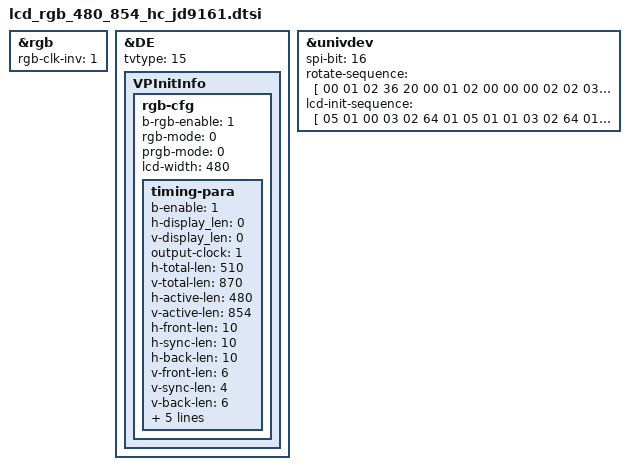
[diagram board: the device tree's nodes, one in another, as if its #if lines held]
&rgb {
	rgb-clk-inv = <1>;
};

&DE {
	tvtype = <15>;
	VPInitInfo {
		rgb-cfg{
			b-rgb-enable = <1>;
			/*
			 * 0: MODE_PRGB
			 * 1: MODE_SRGB
			 */
			rgb-mode = <0>;
			/*
			 * 0: MODE_PRGB_888_10bit
			 * 1: MODE_PRGB_666
			 */
			prgb-mode = <0>;
			lcd-width = <480>;
			timing-para {
				/* bool type, 0 or 1*/
				b-enable = <1>;

				h-display_len = <0>;
				v-display_len = <0>;

				/*
				 * VPO_RGB_CLOCK_27M = 1,
				 * VPO_RGB_CLOCK_33M = 2,
				 * VPO_RGB_CLOCK_49M = 3,
				 * VPO_RGB_CLOCK_66M = 4,
				 * VPO_RGB_CLOCK_74M = 5,
				 * VPO_RGB_CLOCK_85M = 6,
				 * VPO_RGB_CLOCK_108M = 7,
				 * VPO_RGB_CLOCK_6_6M = 8,
				 * VPO_RGB_CLOCK_9M = 9,
				 * VPO_RGB_CLOCK_39_6M = 10,
				 * VPO_RGB_CLOCK_74_25M = 11,
				 * VPO_RGB_CLOCK_148_5M = 12,
				 * VPO_RGB_CLOCK_54M = 13,
				 * VPO_RGB_CLOCK_132M = 14,//H1600
				 * VPO_RGB_CLOCK_297M = 15,//H1600 only De4k
				 * VPO_RGB_CLOCK_DPLL = 0xFF,//H1600
				*/
				output-clock = <1>;

				h-total-len = <510>;
				v-total-len = <870>;

				h-active-len = <480>;
				v-active-len = <854>;

				h-front-len = <10>;
				h-sync-len = <10>;
				h-back-len = <10>;

				v-front-len = <6>;
				v-sync-len = <4>;
				v-back-len = <6>;

				/* bool type, 0 or 1*/
				h-sync-level = <0>;
				/* bool type, 0 or 1*/
				v-sync-level = <0>;

				/* bool type, 0 or 1*/
				active-polarity = <1>;
				frame-rate = <60000>;

				/*
				31	De_dig_pll_en
				25:16	DE_DIG_PLL_M_ctrl
				13:8	DE_DIG_PLL_N_ctrl
				5:0	DE_DIG_PLL_L_ctrl
				de_digpll_clock = 24 *(M+1)/((N+1)*(L+1))
				*/
				dpll-clock-reg-value = <0x0>;
			};
		};
	};
};

#ifdef LCD_UNIVDEV_ENABLED
&univdev{
	spi-bit = <16>;
	rotate-sequence = [	//direction cmds length data
		00 01 02 36 20
		00 01 02 00 00
		00 02 02 03 40
		01 01 02 36 20
		01 01 02 00 00
		01 02 02 02 40
	];
	lcd-init-sequence = [
	05 01 00
	03 02 64 01
	05 01 01
	03 02 64 01
	01 02 ff 20
	01 02 00 00
	02 02 80 40
	01 02 ff 20
	01 02 01 00
	02 02 09 40
	01 02 ff 20
	01 02 02 00
	02 02 01 40
	01 02 ff 20
	01 02 80 00
	02 02 80 40
	01 02 ff 20
	01 02 81 00
	02 02 09 40
	01 02 c4 20
	01 02 80 00
	02 02 30 40
	01 02 c4 20
	01 02 8a 00
	02 02 40 40
	01 02 f5 20
	01 02 b2 00
	02 02 15 40
	01 02 f5 20
	01 02 b3 00
	02 02 00 40
	01 02 f5 20
	01 02 b4 00
	02 02 15 40
	01 02 f5 20
	01 02 b5 00
	02 02 00 40
	01 02 b0 20
	01 02 8b 00
	02 02 40 40
	01 02 b0 20
	01 02 c6 00
	02 02 03 40
	01 02 b3 20
	01 02 90 00
	02 02 02 40
	01 02 b3 20
	01 02 92 00
	02 02 40 40
	01 02 b3 20
	01 02 a6 00
	02 02 20 40
	01 02 b3 20
	01 02 a7 00
	02 02 01 40
	01 02 c0 20
	01 02 90 00
	02 02 00 40
	01 02 c0 20
	01 02 91 00
	02 02 44 40
	01 02 c0 20
	01 02 92 00
	02 02 00 40
	01 02 c0 20
	01 02 93 00
	02 02 00 40
	01 02 c0 20
	01 02 94 00
	02 02 00 40
	01 02 c0 20
	01 02 95 00
	02 02 03 40
	01 02 c0 20
	01 02 b4 00
	02 02 10 40
	01 02 c0 20
	01 02 b5 00
	02 02 10 40
	01 02 c1 20
	01 02 81 00
	02 02 66 40
	01 02 c1 20
	01 02 a0 00
	02 02 ea 40
	01 02 c1 20
	01 02 a6 00
	02 02 01 40
	01 02 c1 20
	01 02 a7 00
	02 02 00 40
	01 02 c1 20
	01 02 a8 00
	02 02 00 40
	01 02 c4 20
	01 02 81 00
	02 02 81 40
	01 02 c5 20
	01 02 82 00
	02 02 83 40
	01 02 c5 20
	01 02 90 00
	02 02 96 40
	01 02 c5 20
	01 02 91 00
	02 02 34 40
	01 02 c5 20
	01 02 92 00
	02 02 06 40
	01 02 c5 20
	01 02 93 00
	02 02 91 40
	01 02 c5 20
	01 02 94 00
	02 02 33 40
	01 02 c5 20
	01 02 95 00
	02 02 34 40
	01 02 c5 20
	01 02 96 00
	02 02 23 40
	01 02 c5 20
	01 02 b1 00
	02 02 a9 40
	01 02 c5 20
	01 02 c0 00
	02 02 00 40
	01 02 ce 20
	01 02 80 00
	02 02 86 40
	01 02 ce 20
	01 02 81 00
	02 02 01 40
	01 02 ce 20
	01 02 82 00
	02 02 00 40
	01 02 ce 20
	01 02 83 00
	02 02 85 40
	01 02 ce 20
	01 02 84 00
	02 02 01 40
	01 02 ce 20
	01 02 85 00
	02 02 00 40
	01 02 ce 20
	01 02 a0 00
	02 02 18 40
	01 02 ce 20
	01 02 a1 00
	02 02 05 40
	01 02 ce 20
	01 02 a2 00
	02 02 03 40
	01 02 ce 20
	01 02 a3 00
	02 02 5b 40
	01 02 ce 20
	01 02 a4 00
	02 02 00 40
	01 02 ce 20
	01 02 a5 00
	02 02 00 40
	01 02 ce 20
	01 02 a6 00
	02 02 00 40
	01 02 ce 20
	01 02 a7 00
	02 02 18 40
	01 02 ce 20
	01 02 a8 00
	02 02 04 40
	01 02 ce 20
	01 02 a9 00
	02 02 03 40
	01 02 ce 20
	01 02 aa 00
	02 02 5c 40
	01 02 ce 20
	01 02 ab 00
	02 02 00 40
	01 02 ce 20
	01 02 ac 00
	02 02 00 40
	01 02 ce 20
	01 02 ad 00
	02 02 00 40
	01 02 ce 20
	01 02 b0 00
	02 02 18 40
	01 02 ce 20
	01 02 b1 00
	02 02 03 40
	01 02 ce 20
	01 02 b2 00
	02 02 03 40
	01 02 ce 20
	01 02 b3 00
	02 02 5d 40
	01 02 ce 20
	01 02 b4 00
	02 02 00 40
	01 02 ce 20
	01 02 b5 00
	02 02 00 40
	01 02 ce 20
	01 02 b6 00
	02 02 00 40
	01 02 ce 20
	01 02 b7 00
	02 02 18 40
	01 02 ce 20
	01 02 b8 00
	02 02 02 40
	01 02 ce 20
	01 02 b9 00
	02 02 03 40
	01 02 ce 20
	01 02 ba 00
	02 02 5e 40
	01 02 ce 20
	01 02 bb 00
	02 02 00 40
	01 02 ce 20
	01 02 bc 00
	02 02 00 40
	01 02 ce 20
	01 02 bd 00
	02 02 00 40
	01 02 cf 20
	01 02 c0 00
	02 02 01 40
	01 02 cf 20
	01 02 c1 00
	02 02 01 40
	01 02 cf 20
	01 02 c2 00
	02 02 20 40
	01 02 cf 20
	01 02 c3 00
	02 02 20 40
	01 02 cf 20
	01 02 c4 00
	02 02 00 40
	01 02 cf 20
	01 02 c5 00
	02 02 00 40
	01 02 cf 20
	01 02 c6 00
	02 02 01 40
	01 02 cf 20
	01 02 c7 00
	02 02 00 40
	01 02 cf 20
	01 02 c8 00
	02 02 00 40
	01 02 cf 20
	01 02 c9 00
	02 02 00 40
	01 02 cb 20
	01 02 c0 00
	02 02 00 40
	01 02 cb 20
	01 02 c1 00
	02 02 04 40
	01 02 cb 20
	01 02 c2 00
	02 02 04 40
	01 02 cb 20
	01 02 c3 00
	02 02 04 40
	01 02 cb 20
	01 02 c4 00
	02 02 04 40
	01 02 cb 20
	01 02 c5 00
	02 02 04 40
	01 02 cb 20
	01 02 c6 00
	02 02 00 40
	01 02 cb 20
	01 02 c7 00
	02 02 00 40
	01 02 cb 20
	01 02 c8 00
	02 02 00 40
	01 02 cb 20
	01 02 c9 00
	02 02 00 40
	01 02 cb 20
	01 02 ca 00
	02 02 00 40
	01 02 cb 20
	01 02 cb 00
	02 02 00 40
	01 02 cb 20
	01 02 cc 00
	02 02 00 40
	01 02 cb 20
	01 02 cd 00
	02 02 00 40
	01 02 cb 20
	01 02 ce 00
	02 02 00 40
	01 02 cb 20
	01 02 d0 00
	02 02 00 40
	01 02 cb 20
	01 02 d1 00
	02 02 00 40
	01 02 cb 20
	01 02 d2 00
	02 02 00 40
	01 02 cb 20
	01 02 d3 00
	02 02 00 40
	01 02 cb 20
	01 02 d4 00
	02 02 00 40
	01 02 cb 20
	01 02 d5 00
	02 02 00 40
	01 02 cb 20
	01 02 d6 00
	02 02 04 40
	01 02 cb 20
	01 02 d7 00
	02 02 04 40
	01 02 cb 20
	01 02 d8 00
	02 02 04 40
	01 02 cb 20
	01 02 d9 00
	02 02 04 40
	01 02 cb 20
	01 02 da 00
	02 02 04 40
	01 02 cb 20
	01 02 db 00
	02 02 00 40
	01 02 cb 20
	01 02 dc 00
	02 02 00 40
	01 02 cb 20
	01 02 dd 00
	02 02 00 40
	01 02 cb 20
	01 02 de 00
	02 02 00 40
	01 02 cb 20
	01 02 e0 00
	02 02 00 40
	01 02 cb 20
	01 02 e1 00
	02 02 00 40
	01 02 cb 20
	01 02 e2 00
	02 02 00 40
	01 02 cb 20
	01 02 e3 00
	02 02 00 40
	01 02 cb 20
	01 02 e4 00
	02 02 00 40
	01 02 cb 20
	01 02 e5 00
	02 02 00 40
	01 02 cb 20
	01 02 e6 00
	02 02 00 40
	01 02 cb 20
	01 02 e7 00
	02 02 00 40
	01 02 cb 20
	01 02 e8 00
	02 02 00 40
	01 02 cb 20
	01 02 e9 00
	02 02 00 40
	01 02 cb 20
	01 02 f0 00
	02 02 ff 40
	01 02 cb 20
	01 02 f1 00
	02 02 ff 40
	01 02 cb 20
	01 02 f2 00
	02 02 ff 40
	01 02 cb 20
	01 02 f3 00
	02 02 ff 40
	01 02 cb 20
	01 02 f4 00
	02 02 ff 40
	01 02 cb 20
	01 02 f5 00
	02 02 ff 40
	01 02 cb 20
	01 02 f6 00
	02 02 ff 40
	01 02 cb 20
	01 02 f7 00
	02 02 ff 40
	01 02 cb 20
	01 02 f8 00
	02 02 ff 40
	01 02 cb 20
	01 02 f9 00
	02 02 ff 40
	01 02 cc 20
	01 02 80 00
	02 02 00 40
	01 02 cc 20
	01 02 81 00
	02 02 26 40
	01 02 cc 20
	01 02 82 00
	02 02 09 40
	01 02 cc 20
	01 02 83 00
	02 02 0b 40
	01 02 cc 20
	01 02 84 00
	02 02 01 40
	01 02 cc 20
	01 02 85 00
	02 02 25 40
	01 02 cc 20
	01 02 86 00
	02 02 00 40
	01 02 cc 20
	01 02 87 00
	02 02 00 40
	01 02 cc 20
	01 02 88 00
	02 02 00 40
	01 02 cc 20
	01 02 89 00
	02 02 00 40
	01 02 cc 20
	01 02 90 00
	02 02 00 40
	01 02 cc 20
	01 02 91 00
	02 02 00 40
	01 02 cc 20
	01 02 92 00
	02 02 00 40
	01 02 cc 20
	01 02 93 00
	02 02 00 40
	01 02 cc 20
	01 02 94 00
	02 02 00 40
	01 02 cc 20
	01 02 95 00
	02 02 00 40
	01 02 cc 20
	01 02 96 00
	02 02 00 40
	01 02 cc 20
	01 02 97 00
	02 02 00 40
	01 02 cc 20
	01 02 98 00
	02 02 00 40
	01 02 cc 20
	01 02 99 00
	02 02 00 40
	01 02 cc 20
	01 02 9a 00
	02 02 00 40
	01 02 cc 20
	01 02 9b 00
	02 02 26 40
	01 02 cc 20
	01 02 9c 00
	02 02 0a 40
	01 02 cc 20
	01 02 9d 00
	02 02 0c 40
	01 02 cc 20
	01 02 9e 00
	02 02 02 40
	01 02 cc 20
	01 02 a0 00
	02 02 25 40
	01 02 cc 20
	01 02 a1 00
	02 02 00 40
	01 02 cc 20
	01 02 a2 00
	02 02 00 40
	01 02 cc 20
	01 02 a3 00
	02 02 00 40
	01 02 cc 20
	01 02 a4 00
	02 02 00 40
	01 02 cc 20
	01 02 a5 00
	02 02 00 40
	01 02 cc 20
	01 02 a6 00
	02 02 00 40
	01 02 cc 20
	01 02 a7 00
	02 02 00 40
	01 02 cc 20
	01 02 a8 00
	02 02 00 40
	01 02 cc 20
	01 02 a9 00
	02 02 00 40
	01 02 cc 20
	01 02 aa 00
	02 02 00 40
	01 02 cc 20
	01 02 ab 00
	02 02 00 40
	01 02 cc 20
	01 02 ac 00
	02 02 00 40
	01 02 cc 20
	01 02 ad 00
	02 02 00 40
	01 02 cc 20
	01 02 ae 00
	02 02 00 40
	01 02 cc 20
	01 02 b0 00
	02 02 00 40
	01 02 cc 20
	01 02 b1 00
	02 02 25 40
	01 02 cc 20
	01 02 b2 00
	02 02 0c 40
	01 02 cc 20
	01 02 b3 00
	02 02 0a 40
	01 02 cc 20
	01 02 b4 00
	02 02 02 40
	01 02 cc 20
	01 02 b5 00
	02 02 26 40
	01 02 cc 20
	01 02 b6 00
	02 02 00 40
	01 02 cc 20
	01 02 b7 00
	02 02 00 40
	01 02 cc 20
	01 02 b8 00
	02 02 00 40
	01 02 cc 20
	01 02 b9 00
	02 02 00 40
	01 02 cc 20
	01 02 c0 00
	02 02 00 40
	01 02 cc 20
	01 02 c1 00
	02 02 00 40
	01 02 cc 20
	01 02 c2 00
	02 02 00 40
	01 02 cc 20
	01 02 c3 00
	02 02 00 40
	01 02 cc 20
	01 02 c4 00
	02 02 00 40
	01 02 cc 20
	01 02 c5 00
	02 02 00 40
	01 02 cc 20
	01 02 c6 00
	02 02 00 40
	01 02 cc 20
	01 02 c7 00
	02 02 00 40
	01 02 cc 20
	01 02 c8 00
	02 02 00 40
	01 02 cc 20
	01 02 c9 00
	02 02 00 40
	01 02 cc 20
	01 02 ca 00
	02 02 00 40
	01 02 cc 20
	01 02 cb 00
	02 02 25 40
	01 02 cc 20
	01 02 cc 00
	02 02 0b 40
	01 02 cc 20
	01 02 cd 00
	02 02 09 40
	01 02 cc 20
	01 02 ce 00
	02 02 01 40
	01 02 cc 20
	01 02 d0 00
	02 02 26 40
	01 02 cc 20
	01 02 d1 00
	02 02 00 40
	01 02 cc 20
	01 02 d2 00
	02 02 00 40
	01 02 cc 20
	01 02 d3 00
	02 02 00 40
	01 02 cc 20
	01 02 d4 00
	02 02 00 40
	01 02 cc 20
	01 02 d5 00
	02 02 00 40
	01 02 cc 20
	01 02 d6 00
	02 02 00 40
	01 02 cc 20
	01 02 d7 00
	02 02 00 40
	01 02 cc 20
	01 02 d8 00
	02 02 00 40
	01 02 cc 20
	01 02 d9 00
	02 02 00 40
	01 02 cc 20
	01 02 da 00
	02 02 00 40
	01 02 cc 20
	01 02 db 00
	02 02 00 40
	01 02 cc 20
	01 02 dc 00
	02 02 00 40
	01 02 cc 20
	01 02 dd 00
	02 02 00 40
	01 02 cc 20
	01 02 de 00
	02 02 00 40
	01 02 d8 20
	01 02 00 00
	02 02 77 40
	01 02 d8 20
	01 02 01 00
	02 02 77 40
	01 02 d9 20
	01 02 00 00
	02 02 48 40
	01 02 e1 20
	01 02 00 00
	02 02 01 40
	01 02 e1 20
	01 02 01 00
	02 02 08 40
	01 02 e1 20
	01 02 02 00
	02 02 0d 40
	01 02 e1 20
	01 02 03 00
	02 02 0d 40
	01 02 e1 20
	01 02 04 00
	02 02 05 40
	01 02 e1 20
	01 02 05 00
	02 02 0f 40
	01 02 e1 20
	01 02 06 00
	02 02 0c 40
	01 02 e1 20
	01 02 07 00
	02 02 0b 40
	01 02 e1 20
	01 02 08 00
	02 02 02 40
	01 02 e1 20
	01 02 09 00
	02 02 06 40
	01 02 e1 20
	01 02 0a 00
	02 02 0b 40
	01 02 e1 20
	01 02 0b 00
	02 02 08 40
	01 02 e1 20
	01 02 0c 00
	02 02 0f 40
	01 02 e1 20
	01 02 0d 00
	02 02 12 40
	01 02 e1 20
	01 02 0e 00
	02 02 0d 40
	01 02 e1 20
	01 02 0f 00
	02 02 03 40
	01 02 e2 20
	01 02 00 00
	02 02 01 40
	01 02 e2 20
	01 02 01 00
	02 02 08 40
	01 02 e2 20
	01 02 02 00
	02 02 0d 40
	01 02 e2 20
	01 02 03 00
	02 02 0d 40
	01 02 e2 20
	01 02 04 00
	02 02 05 40
	01 02 e2 20
	01 02 05 00
	02 02 0f 40
	01 02 e2 20
	01 02 06 00
	02 02 0c 40
	01 02 e2 20
	01 02 07 00
	02 02 0b 40
	01 02 e2 20
	01 02 08 00
	02 02 02 40
	01 02 e2 20
	01 02 09 00
	02 02 06 40
	01 02 e2 20
	01 02 0a 00
	02 02 0b 40
	01 02 e2 20
	01 02 0b 00
	02 02 08 40
	01 02 e2 20
	01 02 0c 00
	02 02 0f 40
	01 02 e2 20
	01 02 0d 00
	02 02 12 40
	01 02 e2 20
	01 02 0e 00
	02 02 0d 40
	01 02 e2 20
	01 02 0f 00
	02 02 03 40
	01 02 c1 20
	01 02 a0 00
	02 02 ea 40
	01 02 c1 20
	01 02 a6 00
	02 02 01 40
	01 02 c1 20
	01 02 a7 00
	02 02 00 40
	01 02 c1 20
	01 02 a8 00
	02 02 00 40
	01 02 b0 20
	01 02 c6 00
	02 02 03 40
	01 02 c5 20
	01 02 81 00
	02 02 66 40
	01 02 f5 20
	01 02 b6 00
	02 02 06 40
	01 02 b0 20
	01 02 8b 00
	02 02 40 40
	01 02 ff 20
	01 02 00 00
	02 02 ff 40
	01 02 ff 20
	01 02 01 00
	02 02 ff 40
	01 02 ff 20
	01 02 02 00
	02 02 ff 40
	01 02 11 20
	01 02 00 00
	02 02 00 40
	03 01 78
	01 02 29 20
	01 02 00 00
	02 02 00 40
	03 01 78
	];
};
#endif
